# moondancer register map
Vendor: luna-soc
Registers are 8-bit, read-write, reset 0x0 unless marked. A register's access mark holds for its fields unless they carry their own. Offsets are from the block's base; [hi:lo] are bit positions; {n}, {i} and the like mark numbered series.

## gpio0
Base 0xF0000100
Same registers: gpio1 0xF0000200
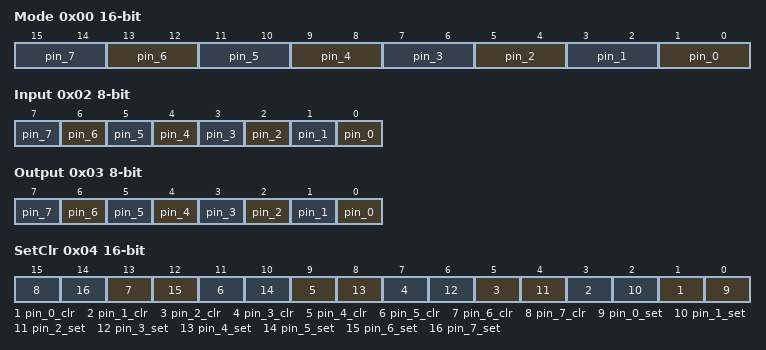
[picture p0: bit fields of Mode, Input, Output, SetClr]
0x00 Mode 16-bit — Mode register. This :class:`csr.Register` contains an array of ``pin_count`` read/write fields. Each field is 2-bit wide and its possible values are defined by the :class:`PinMode` enumeration. If ``pin_count`` is 8, then the register has the following fields: .. bitfield:: :bits: 16 [ { "name": "pin[0]", "bits": 2, "attr": "RW" }, { "name": "pin[1]", "bits": 2, "attr": "RW" }, { "name": "pin[2]", "bits": 2, "attr": "RW" }, { "name": "pin[3]", "bits": 2, "attr": "RW" }, { "name": "pin[4]", "bits": 2, "attr": "RW" }, { "name": "pin[5]", "bits": 2, "attr": "RW" }, { "name": "pin[6]", "bits": 2, "attr": "RW" }, { "name": "pin[7]", "bits": 2, "attr": "RW" }, ] Parameters ---------- pin_count : :class:`int` Number of GPIO pins.
  [2n+1:2n] pin_{n} (n=0..7)
0x02 Input — Input register. This :class:`csr.Register` contains an array of ``pin_count`` read-only fields. Each field is 1-bit wide and driven by the input of its associated pin in the :attr:`Peripheral.pins` array. Values sampled from pin inputs go through :attr:`Peripheral.input_stages` synchronization stages (on a rising edge of ``ClockSignal("sync")``) before reaching the register. If ``pin_count`` is 8, then the register has the following fields: .. bitfield:: :bits: 8 [ { "name": "pin[0]", "bits": 1, "attr": "R" }, { "name": "pin[1]", "bits": 1, "attr": "R" }, { "name": "pin[2]", "bits": 1, "attr": "R" }, { "name": "pin[3]", "bits": 1, "attr": "R" }, { "name": "pin[4]", "bits": 1, "attr": "R" }, { "name": "pin[5]", "bits": 1, "attr": "R" }, { "name": "pin[6]", "bits": 1, "attr": "R" }, { "name": "pin[7]", "bits": 1, "attr": "R" }, ] Parameters ---------- pin_count : :class:`int` Number of GPIO pins.
  [n] pin_{n} ro (n=0..7)
0x03 Output — Output register. This :class:`csr.Register` contains an array of ``pin_count`` read/write fields. Each field is 1-bit wide and drives the output of its associated pin in the :attr:`Peripheral.pins` array, depending on its associated :class:`~Peripheral.Mode` field. If ``pin_count`` is 8, then the register has the following fields: .. bitfield:: :bits: 8 [ { "name": "pin[0]", "bits": 1, "attr": "RW" }, { "name": "pin[1]", "bits": 1, "attr": "RW" }, { "name": "pin[2]", "bits": 1, "attr": "RW" }, { "name": "pin[3]", "bits": 1, "attr": "RW" }, { "name": "pin[4]", "bits": 1, "attr": "RW" }, { "name": "pin[5]", "bits": 1, "attr": "RW" }, { "name": "pin[6]", "bits": 1, "attr": "RW" }, { "name": "pin[7]", "bits": 1, "attr": "RW" }, ] Parameters ---------- pin_count : :class:`int` Number of GPIO pins.
  [n] pin_{n} (n=0..7)
0x04 SetClr 16-bit — Output set/clear register. This :class:`csr.Register` contains an array of ``pin_count`` write-only fields. Each field is 2-bit wide; writing it can modify its associated :class:`~Peripheral.Output` field as a side-effect. If ``pin_count`` is 8, then the register has the following fields: .. bitfield:: :bits: 16 [ { "name": "pin[0]", "bits": 2, "attr": "W" }, { "name": "pin[1]", "bits": 2, "attr": "W" }, { "name": "pin[2]", "bits": 2, "attr": "W" }, { "name": "pin[3]", "bits": 2, "attr": "W" }, { "name": "pin[4]", "bits": 2, "attr": "W" }, { "name": "pin[5]", "bits": 2, "attr": "W" }, { "name": "pin[6]", "bits": 2, "attr": "W" }, { "name": "pin[7]", "bits": 2, "attr": "W" }, ] - Writing `0b01` to a field sets its associated :class:`~Peripheral.Output` field. - Writing `0b10` to a field clears its associated :class:`~Peripheral.Output` field. - Writing `0b00` or `0b11` to a field has no side-effect. Parameters ---------- pin_count : :class:`int` Number of GPIO pins.
  [2n+1] pin_{n}_clr wo (n=0..7), [2n] pin_{n}_set wo (n=0..7)

## uart0
Base 0xF0000300
Same registers: uart1 0xF0000400
0x00 tx_data — valid to write to when tx_rdy is high, will trigger a transmit
  [7:0] data wo
0x04 rx_data — valid to read from when rx_avail is high, last received byte
  [7:0] data ro
0x08 tx_ready — is '1' when 1-byte transmit buffer is empty
  [0] txe ro
0x0C rx_avail — is '1' when 1-byte receive buffer is full; reset by a read from rx_data
  [0] rxe ro
0x10 divisor 32-bit — baud rate divider, defaults to init
  [23:0] div
